# SN32F780 register map
Vendor: SONiX Technology Co., Ltd.; Series: SN32F780; File version: 0.75
CPU: CM0 r0p0, little endian, no MPU, no FPU, 2 interrupt priority bits
Registers are 32-bit, read-write, reset 0x0 unless marked. A register's access mark holds for its fields unless they carry their own. Offsets are from the block's base; [hi:lo] are bit positions; {n}, {i} and the like mark numbered series; 'fields as' and 'values as' point back to an identical list.

## SN_SYS1 — System Control Registers 1
Base 0x4005E000
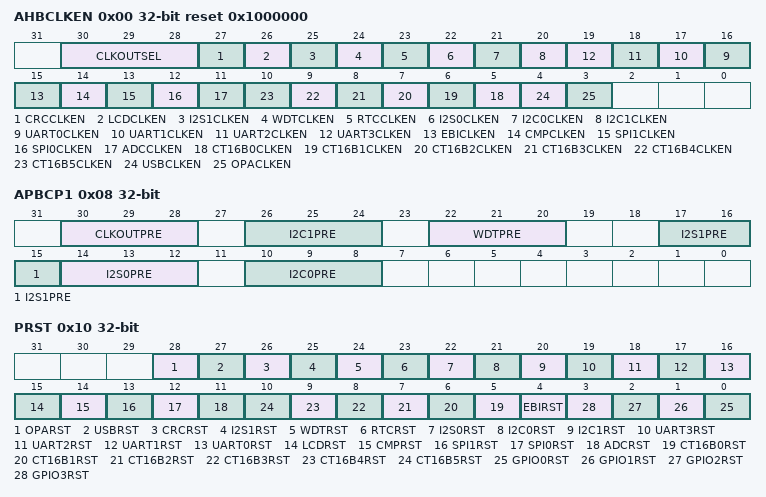
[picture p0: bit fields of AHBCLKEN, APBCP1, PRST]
0x00 AHBCLKEN reset 0x1000000 — Offset:0x00 AHB Clock Enable Register
  [30:28] CLKOUTSEL — Clock output source selection
    0=000b (Disable); 1=001b (ILRC); 2=010b (ELS XTAL); 3=011b (CS Clockout selected by SGSEL[1:0] bits); 4=100b (HCLK); 5=101b (IHRC); 6=110b (EHS XTAL); 7=111b (PLL output)
  [27] CRCCLKEN — Enable AHB clock for CRC
    0=Disable; 1=Enable
  [26] LCDCLKEN — Enable AHB clock for LCD
    0=Disable; 1=Enable
  [25] I2S1CLKEN — Enable AHB clock for I2S1
    0=Disable; 1=Enable
  [24] WDTCLKEN — Enable AHB clock for WDT
    0=Disable; 1=Enable
  [23] RTCCLKEN — Enable AHB clock for RTC
    0=Disable; 1=Enable
  [22] I2S0CLKEN — Enable AHB clock for I2S0
    0=Disable; 1=Enable
  [21] I2C0CLKEN — Enable AHB clock for I2C0
    0=Disable; 1=Enable
  [20] I2C1CLKEN — Enable AHB clock for I2C1
    0=Disable; 1=Enable
  [n+16] UART{n}CLKEN (n=0..3) — Enable AHB clock for UART{n}
    0=Disable; 1=Enable
  [15] EBICLKEN — Enable AHB clock for EBI
    0=Disable; 1=Enable
  [14] CMPCLKEN — Enable AHB clock for CMP
    0=Disable; 1=Enable
  [13] SPI1CLKEN — Enable AHB clock for SPI1
    0=Disable; 1=Enable
  [12] SPI0CLKEN — Enable AHB clock for SPI0
    0=Disable; 1=Enable
  [11] ADCCLKEN — Enable AHB clock for ADC
    0=Disable; 1=Enable
  [n+5] CT16B{n}CLKEN (n=0..5) — Enable AHB clock for CT16B{n}
    0=Disable; 1=Enable
  [4] USBCLKEN — Enable AHB clock for USB
    0=Disable; 1=Enable
  [3] OPACLKEN — Enable AHB clock for OPA
    0=Disable; 1=Enable
0x04 APBCP0 — Offset:0x04 APB Clock Prescale Register 0
  [18:16] ADCPRE — ADC APB clock source prescaler
    0=000b (HCLK/1); 1=001b (HCLK/2); 2=010b (HCLK/4); 3=011b (HCLK/8); 4=100b (HCLK/16)
0x08 APBCP1 — Offset:0x08 APB Clock Prescale Register 1
  [30:28] CLKOUTPRE — CLKOUT APB clock source prescaler
    0=000b (FCLKOUT/1); 1=001b (FCLKOUT/2); 2=010b (FCLKOUT/4); 3=011b (FCLKOUT/8); 4=100b (FCLKOUT/16); 5=101b (FCLKOUT/32); 6=110b (FCLKOUT/64); 7=111b (FCLKOUT/128)
  [26:24] I2C1PRE wo — I2C1 APB clock source prescaler
    values as APBCP0.ADCPRE
  [22:20] WDTPRE — WDT APB clock source prescaler
    0=000b (WDT_PCLK = WDT clock source / 1); 1=001b (WDT_PCLK = WDT clock source / 2); 2=010b (WDT_PCLK = WDT clock source / 4); 3=011b (WDT_PCLK = WDT clock source / 8); 4=100b (WDT_PCLK = WDT clock source / 16); 5=101b (WDT_PCLK = WDT clock source / 32)
  [17:15] I2S1PRE — I2S1 APB clock source prescaler
    0=000b (HCLK/1); 1=001b (HCLK/2); 2=010b (HCLK/4); 3=011b (HCLK/8); 4=100b (HCLK/16); 7=111b (HCLK/3)
  [14:12] I2S0PRE — I2S0 APB clock source prescaler
    values as I2S1PRE
  [10:8] I2C0PRE wo — I2C0 APB clock source prescaler
    values as APBCP0.ADCPRE
0x10 PRST — Offset:0x10 Peripheral Reset Register
  [28] OPARST — USB Reset
    0=No effect; 1=Reset OPA
  [27] USBRST — USB Reset
    0=No effect; 1=Reset USB
  [26] CRCRST — CRC Reset
    0=No effect; 1=Reset CRC
  [25] I2S1RST — I2S1 Reset
    0=No effect; 1=Reset I2S1
  [24] WDTRST — WDT Reset
    0=No effect; 1=Reset WDT
  [23] RTCRST — RTC Reset
    0=No effect; 1=Reset RTC
  [22] I2S0RST — I2S0 Reset
    0=No effect; 1=Reset I2S0
  [21] I2C0RST — I2C0 Reset
    0=No effect; 1=Reset I2C0
  [20] I2C1RST — I2C1 Reset
    0=No effect; 1=Reset I2C1
  [19] UART3RST — UART1 Reset
    0=No effect; 1=Reset UART3
  [18] UART2RST — UART2 Reset
    0=No effect; 1=Reset UART2
  [17] UART1RST — UART1 Reset
    0=No effect; 1=Reset UART1
  [16] UART0RST — UART0 Reset
    0=No effect; 1=Reset UART0
  [15] LCDRST — LCD Reset
    0=No effect; 1=Reset LCD
  [14] CMPRST — CMP Reset
    0=No effect; 1=Reset CMP
  [13] SPI1RST — SPI1 Reset
    0=No effect; 1=Reset SPI1
  [12] SPI0RST — SPI0 Reset
    0=No effect; 1=Reset SPI0
  [11] ADCRST — ADC Reset
    0=No effect; 1=Reset ADC
  [n+5] CT16B{n}RST (n=0..5) — CT16B{n} Reset
    0=No effect; 1=Reset CT16B{n}
  [4] EBIRST — EBI Reset
    0=No effect; 1=Reset GPIO3
  [n] GPIO{n}RST (n=0..3) — GPIO{n} Reset
    0=No effect; 1=Reset GPIO{n}
